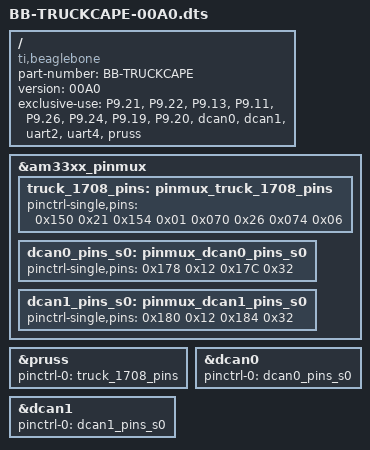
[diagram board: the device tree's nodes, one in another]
/*
 * Originals Copyright (C) 2013 CircuitCo
 *
 * TruckCape DTS hacked together from CircuitCo pieces by Haystack in 2016
 *
 * This program is free software; you can redistribute it and/or modify
 * it under the terms of the GNU General Public License version 2 as
 * published by the Free Software Foundation.
 */
/dts-v1/;
/plugin/;

/ {
	compatible = "ti,beaglebone", "ti,beaglebone-black";

	/* identification */
	part-number = "BB-TRUCKCAPE";
	version = "00A0";

	/* state the resources this cape uses */
	exclusive-use =
		/* the pin header uses */
		"P9.21",	/* uart2_txd */
		"P9.22",	/* uart2_rxd */
    "P9.13",	/* uart4_txd */
		"P9.11",	/* uart4_rxd */
    "P9.26",		/* dcan1: dcan1_tx */
		"P9.24",		/* dcan1: dcan1_rx */
    "P9.19",  /* dcan0: dcan0_rx */
    "P9.20",  /* dcan0: dcan0_tx */
		/* the hardware ip uses */
    "dcan0",
    "dcan1",
		"uart2",
    "uart4",
		"pruss";

	fragment@0 {
		target = <&am33xx_pinmux>;
		__overlay__ {
			truck_1708_pins: pinmux_truck_1708_pins {
				pinctrl-single,pins = <
					0x150 0x21	/* spi0_sclk.uart2_rxd | MODE1 */
					0x154 0x01	/* spi0_d0.uart2_txd | MODE1 */
          0x070 0x26	/* spi0_sclk.uart2_rxd | MODE1 */
					0x074 0x06	/* spi0_d0.uart2_txd | MODE1 */

				>;
			};
		};
	};

  fragment@1 {
    target = <&am33xx_pinmux>;
    __overlay__ {
       dcan0_pins_s0: pinmux_dcan0_pins_s0 {
          pinctrl-single,pins = <
            0x178 0x12  /* d_can0_tx, SLEWCTRL_FAST | INPUT_PULLUP | MODE2 */
            0x17C 0x32  /* d_can0_rx, SLEWCTRL_FAST | RECV_ENABLE | INPUT_PULLUP | MODE2 */
           >;
        };
     };
   };

  fragment@2 {
    target = <&am33xx_pinmux>;
    __overlay__ {
       dcan1_pins_s0: pinmux_dcan1_pins_s0 {
           pinctrl-single,pins = <
              0x180 0x12  /* uart1_rxd.d_can1_tx", OUTPUT | MODE2 */
		     			0x184 0x32  /* uart1_txd.d_can1_rx", INPUT_PULLUP | MODE2 */
           >;
       };
     };
  };




	fragment@3 {
		target = <&pruss>;
		__overlay__ {
			status = "okay";
			pinctrl-names = "default";
			pinctrl-0 = <&truck_1708_pins>;

		};
	};

	fragment@4 {
		target = <&dcan0>;
		__overlay__ {
			status = "okay";
			pinctrl-names = "default";
			pinctrl-0 = <&dcan0_pins_s0>;
		};
	};

  fragment@5 {
     target = <&dcan1>;
     __overlay__ {
        status = "okay";
        pinctrl-names = "default";
        pinctrl-0 = <&dcan1_pins_s0>;
     };

  };
    
};
